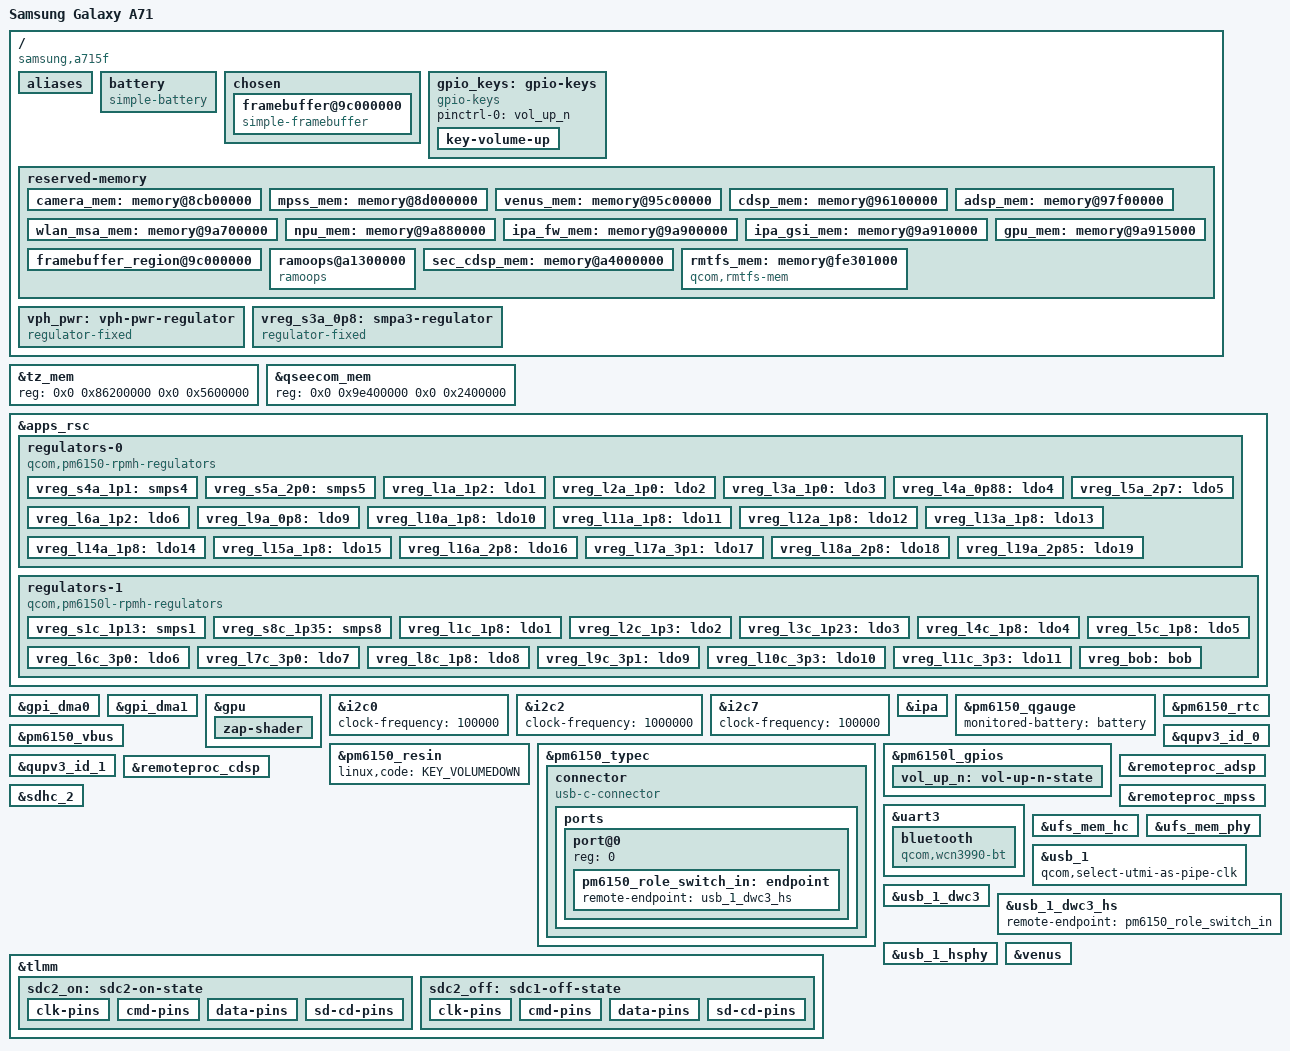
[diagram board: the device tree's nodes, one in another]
// SPDX-License-Identifier: BSD-3-Clause
/*
 * Copyright (c) 2023, Danila Tikhonov <danila@jiaxyga.com>
 * Copyright (c) 2025, Waldemar Tomme <waldetomme@gmail.com>
 */

/dts-v1/;

#include <dt-bindings/arm/qcom,ids.h>
#include <dt-bindings/firmware/qcom,scm.h>
#include <dt-bindings/gpio/gpio.h>
#include <dt-bindings/leds/common.h>
#include <dt-bindings/pinctrl/qcom,pmic-gpio.h>
#include <dt-bindings/regulator/qcom,rpmh-regulator.h>
#include <dt-bindings/usb/pd.h>

#include "sm7150.dtsi"
#include "pm6150.dtsi"
#include "pm6150l.dtsi"

/delete-node/ &camera_mem;
/delete-node/ &mpss_mem;
/delete-node/ &venus_mem;
/delete-node/ &cdsp_mem;
/delete-node/ &adsp_mem;
/delete-node/ &wlan_msa_mem;
/delete-node/ &npu_mem;
/delete-node/ &ipa_fw_mem;
/delete-node/ &ipa_gsi_mem;
/delete-node/ &gpu_mem;
/delete-node/ &sec_cdsp_mem;

/* Increase the size */
&tz_mem {
	reg = <0x0 0x86200000 0x0 0x5600000>;
};

&qseecom_mem {
	reg = <0x0 0x9e400000 0x0 0x2400000>;
};

/ {
	model = "Samsung Galaxy A71";
	compatible = "samsung,a715f", "qcom,sm7150";
	chassis-type = "handset";

	aliases {
		bluetooth0 = &bluetooth;
		hsuart0 = &uart3;
		wifi0 = &wifi;
	};

	battery: battery {
		compatible = "simple-battery";

		voltage-min-design-microvolt = <3400000>;
		voltage-max-design-microvolt = <4400000>;
		charge-full-design-microamp-hours = <4500000>;
	};

	chosen {
		#address-cells = <2>;
		#size-cells = <2>;
		ranges;
		framebuffer@9c000000 {
			compatible = "simple-framebuffer";
			reg = <0x0 0x9c000000 0x0 (1080 * 2400 * 4)>;
			width = <1080>;
			height = <2400>;
			stride = <(1080 * 4)>;
			format = "a8r8g8b8";
			clocks = <&gcc GCC_DISP_HF_AXI_CLK>;
		};
	};

	gpio_keys: gpio-keys {
		compatible = "gpio-keys";
		pinctrl-names = "default";
		pinctrl-0 = <&vol_up_n>;

		key-volume-up {
			label = "Volume Up";
			linux,code = <KEY_VOLUMEUP>;
			gpios = <&pm6150l_gpios 2 GPIO_ACTIVE_LOW>;
			debounce-interval = <15>;
		};
	};

	reserved-memory {
		camera_mem: memory@8cb00000 {
			reg = <0x0 0x8cb00000 0x0 0x500000>;
			no-map;
		};

		mpss_mem: memory@8d000000 {
			reg = <0x0 0x8d000000 0x0 0x8c00000>;
			no-map;
		};

		venus_mem: memory@95c00000 {
			reg = <0x0 0x95c00000 0x0 0x500000>;
			no-map;
		};

		cdsp_mem: memory@96100000 {
			reg = <0x0 0x96100000 0x0 0x1e00000>;
			no-map;
		};

		adsp_mem: memory@97f00000 {
			reg = <0x0 0x97f00000 0x0 0x2800000>;
			no-map;
		};

		wlan_msa_mem: memory@9a700000 {
			reg = <0x0 0x9a700000 0x0 0x180000>;
			no-map;
		};

		npu_mem: memory@9a880000 {
			reg = <0x0 0x9a880000 0x0 0x80000>;
			no-map;
		};

		ipa_fw_mem: memory@9a900000 {
			reg = <0x0 0x9a900000 0x0 0x10000>;
			no-map;
		};

		ipa_gsi_mem: memory@9a910000 {
			reg = <0x0 0x9a910000 0x0 0x5000>;
			no-map;
		};

		gpu_mem: memory@9a915000 {
			reg = <0x0 0x9a915000 0x0 0x2000>;
			no-map;
		};

		framebuffer_region@9c000000 {
			reg = <0x0 0x9c000000 0x0 (1080 * 2400 * 4)>;
			no-map;
		};

		ramoops@a1300000 {
			compatible = "ramoops";
			reg = <0x0 0xa1300000 0x0 0x100000>;

			record-size = <0x40000>;
			pmsg-size = <0x40000>;
			console-size = <0x40000>;
		};

		sec_cdsp_mem: memory@a4000000 {
			reg = <0x0 0xa4000000 0x0 0xc00000>;
			no-map;
		};

		rmtfs_mem: memory@fe301000 {
			compatible = "qcom,rmtfs-mem";
			reg = <0 0xfe301000 0 0x200000>;
			no-map;

			qcom,client-id = <1>;
			qcom,vmid = <15>;
		};
	};

	vph_pwr: vph-pwr-regulator {
		compatible = "regulator-fixed";
		regulator-name = "vph_pwr";
		regulator-min-microvolt = <3700000>;
		regulator-max-microvolt = <3700000>;
	};

	// S3A is really mx.lvl but it's there for supply map completeness sake.
	vreg_s3a_0p8: smpa3-regulator {
		compatible = "regulator-fixed";
		regulator-name = "vreg_s3a_0p8";

		regulator-min-microvolt = <800000>;
		regulator-max-microvolt = <800000>;
		regulator-always-on;
		vin-supply = <&vph_pwr>;
	};
};

&apps_rsc {
	regulators-0 {
		compatible = "qcom,pm6150-rpmh-regulators";
		qcom,pmic-id = "a";

		vdd-s1-supply = <&vph_pwr>;
		vdd-s2-supply = <&vph_pwr>;
		vdd-s3-supply = <&vph_pwr>;
		vdd-s4-supply = <&vph_pwr>;
		vdd-s5-supply = <&vph_pwr>;

		vdd-l1-supply = <&vreg_s8c_1p35>;
		vdd-l2-l3-supply = <&vreg_s4a_1p1>;
		vdd-l4-l7-l8-supply = <&vreg_s4a_1p1>;
		vdd-l5-l16-l17-l18-l19-supply = <&vreg_bob>;
		vdd-l6-supply = <&vreg_s8c_1p35>;
		vdd-l9-supply = <&vreg_s3a_0p8>;
		vdd-l10-l14-l15-supply = <&vreg_s5a_2p0>;
		vdd-l11-l12-l13-supply = <&vreg_s5a_2p0>;

		vreg_s4a_1p1: smps4 {
			regulator-name = "vreg_s4a_1p1";
			regulator-min-microvolt = <824000>;
			regulator-max-microvolt = <1120000>;
		};

		vreg_s5a_2p0: smps5 {
			regulator-name = "vreg_s5a_2p0";
			regulator-min-microvolt = <1744000>;
			regulator-max-microvolt = <2040000>;
		};

		vreg_l1a_1p2: ldo1 {
			regulator-name = "vreg_l1a_1p2";
			regulator-min-microvolt = <1096000>;
			regulator-max-microvolt = <1304000>;
			regulator-initial-mode = <RPMH_REGULATOR_MODE_HPM>;
			regulator-allow-set-load;
			regulator-allowed-modes = <RPMH_REGULATOR_MODE_LPM
						   RPMH_REGULATOR_MODE_HPM>;
		};

		vreg_l2a_1p0: ldo2 {
			regulator-name = "vreg_l2a_1p0";
			regulator-min-microvolt = <944000>;
			regulator-max-microvolt = <1056000>;
			regulator-initial-mode = <RPMH_REGULATOR_MODE_HPM>;
			regulator-allow-set-load;
			regulator-allowed-modes = <RPMH_REGULATOR_MODE_LPM
						   RPMH_REGULATOR_MODE_HPM>;
		};

		vreg_l3a_1p0: ldo3 {
			regulator-name = "vreg_l3a_1p0";
			regulator-min-microvolt = <968000>;
			regulator-max-microvolt = <1064000>;
			regulator-initial-mode = <RPMH_REGULATOR_MODE_HPM>;
			regulator-allow-set-load;
			regulator-allowed-modes = <RPMH_REGULATOR_MODE_LPM
						   RPMH_REGULATOR_MODE_HPM>;
		};

		vreg_l4a_0p88: ldo4 {
			regulator-name = "vreg_l4a_0p88";
			regulator-min-microvolt = <824000>;
			regulator-max-microvolt = <920000>;
			regulator-initial-mode = <RPMH_REGULATOR_MODE_HPM>;
			regulator-allow-set-load;
			regulator-allowed-modes = <RPMH_REGULATOR_MODE_LPM
						   RPMH_REGULATOR_MODE_HPM>;
		};

		vreg_l5a_2p7: ldo5 {
			regulator-name = "vreg_l5a_2p7";
			regulator-min-microvolt = <2600000>;
			regulator-max-microvolt = <2800000>;
			regulator-initial-mode = <RPMH_REGULATOR_MODE_HPM>;
			regulator-allow-set-load;
			regulator-allowed-modes = <RPMH_REGULATOR_MODE_LPM
						   RPMH_REGULATOR_MODE_HPM>;
		};

		vreg_l6a_1p2: ldo6 {
			regulator-name = "vreg_l6a_1p2";
			regulator-min-microvolt = <1096000>;
			regulator-max-microvolt = <1304000>;
			regulator-initial-mode = <RPMH_REGULATOR_MODE_HPM>;
			regulator-allow-set-load;
			regulator-allowed-modes = <RPMH_REGULATOR_MODE_LPM
						   RPMH_REGULATOR_MODE_HPM>;
		};

		vreg_l9a_0p8: ldo9 {
			regulator-name = "vreg_l9a_0p8";
			regulator-min-microvolt = <624000>;
			regulator-max-microvolt = <760000>;
			regulator-initial-mode = <RPMH_REGULATOR_MODE_HPM>;
			regulator-allow-set-load;
			regulator-allowed-modes = <RPMH_REGULATOR_MODE_LPM
						   RPMH_REGULATOR_MODE_HPM>;
		};

		vreg_l10a_1p8: ldo10 {
			regulator-name = "vreg_l10a_1p8";
			regulator-min-microvolt = <1720000>;
			regulator-max-microvolt = <1832000>;
			regulator-initial-mode = <RPMH_REGULATOR_MODE_HPM>;
			regulator-allow-set-load;
			regulator-allowed-modes = <RPMH_REGULATOR_MODE_LPM
						   RPMH_REGULATOR_MODE_HPM>;
		};

		vreg_l11a_1p8: ldo11 {
			regulator-name = "vreg_l11a_1p8";
			regulator-min-microvolt = <1696000>;
			regulator-max-microvolt = <1984000>;
			regulator-initial-mode = <RPMH_REGULATOR_MODE_HPM>;
			regulator-allow-set-load;
			regulator-allowed-modes = <RPMH_REGULATOR_MODE_LPM
						   RPMH_REGULATOR_MODE_HPM>;
		};

		vreg_l12a_1p8: ldo12 {
			regulator-name = "vreg_l12a_1p8";
			regulator-min-microvolt = <1696000>;
			regulator-max-microvolt = <1952000>;
			regulator-initial-mode = <RPMH_REGULATOR_MODE_HPM>;
			regulator-allow-set-load;
			regulator-allowed-modes = <RPMH_REGULATOR_MODE_LPM
						   RPMH_REGULATOR_MODE_HPM>;
		};

		vreg_l13a_1p8: ldo13 {
			regulator-name = "vreg_l13a_1p8";
			regulator-min-microvolt = <1696000>;
			regulator-max-microvolt = <1904000>;
			regulator-initial-mode = <RPMH_REGULATOR_MODE_HPM>;
			regulator-allow-set-load;
			regulator-allowed-modes = <RPMH_REGULATOR_MODE_LPM
						   RPMH_REGULATOR_MODE_HPM>;
		};

		vreg_l14a_1p8: ldo14 {
			regulator-name = "vreg_l14a_1p8";
			regulator-min-microvolt = <1720000>;
			regulator-max-microvolt = <1856000>;
			regulator-initial-mode = <RPMH_REGULATOR_MODE_HPM>;
			regulator-allow-set-load;
			regulator-allowed-modes = <RPMH_REGULATOR_MODE_LPM
						   RPMH_REGULATOR_MODE_HPM>;
		};

		vreg_l15a_1p8: ldo15 {
			regulator-name = "vreg_l15a_1p8";
			regulator-min-microvolt = <1696000>;
			regulator-max-microvolt = <1904000>;
			regulator-initial-mode = <RPMH_REGULATOR_MODE_HPM>;
			regulator-allow-set-load;
			regulator-allowed-modes = <RPMH_REGULATOR_MODE_LPM
						   RPMH_REGULATOR_MODE_HPM>;
		};

		vreg_l16a_2p8: ldo16 {
			regulator-name = "vreg_l16a_2p8";
			regulator-min-microvolt = <2424000>;
			regulator-max-microvolt = <2976000>;
			regulator-initial-mode = <RPMH_REGULATOR_MODE_HPM>;
			regulator-allow-set-load;
			regulator-allowed-modes = <RPMH_REGULATOR_MODE_LPM
						   RPMH_REGULATOR_MODE_HPM>;
		};

		vreg_l17a_3p1: ldo17 {
			regulator-name = "vreg_l17a_3p1";
			regulator-min-microvolt = <3000000>;
			regulator-max-microvolt = <3232000>;
			regulator-initial-mode = <RPMH_REGULATOR_MODE_HPM>;
			regulator-allow-set-load;
			regulator-allowed-modes = <RPMH_REGULATOR_MODE_LPM
						   RPMH_REGULATOR_MODE_HPM>;
		};

		vreg_l18a_2p8: ldo18 {
			regulator-name = "vreg_l18a_2p8";
			regulator-min-microvolt = <2800000>;
			regulator-max-microvolt = <3000000>;
			regulator-initial-mode = <RPMH_REGULATOR_MODE_HPM>;
			regulator-allow-set-load;
			regulator-allowed-modes = <RPMH_REGULATOR_MODE_LPM
						   RPMH_REGULATOR_MODE_HPM>;
		};

		vreg_l19a_2p85: ldo19 {
			regulator-name = "vreg_l19a_2p85";
			regulator-min-microvolt = <2944000>;
			regulator-max-microvolt = <3304000>;
			regulator-initial-mode = <RPMH_REGULATOR_MODE_HPM>;
			regulator-allow-set-load;
			regulator-allowed-modes = <RPMH_REGULATOR_MODE_LPM
						   RPMH_REGULATOR_MODE_HPM>;
		};
	};

	regulators-1 {
		compatible = "qcom,pm6150l-rpmh-regulators";
		qcom,pmic-id = "c";

		vdd-s1-supply = <&vph_pwr>;
		vdd-s2-supply = <&vph_pwr>;
		vdd-s3-supply = <&vph_pwr>;
		vdd-s4-supply = <&vph_pwr>;
		vdd-s5-supply = <&vph_pwr>;
		vdd-s6-supply = <&vph_pwr>;
		vdd-s7-supply = <&vph_pwr>;
		vdd-s8-supply = <&vph_pwr>;

		vdd-l2-l3-supply = <&vreg_s8c_1p35>;
		vdd-l4-l5-l6-supply = <&vreg_bob>;
		vdd-l7-l11-supply = <&vreg_bob>;
		vdd-l9-l10-supply = <&vreg_bob>;

		vdd-bob-supply = <&vph_pwr>;
		vdd-flash-supply = <&vreg_bob>;
		vdd-rgb-supply = <&vreg_bob>;

		vreg_s1c_1p13: smps1 {
			regulator-name = "vreg_s1c_1p13";
			regulator-min-microvolt = <1000000>;
			regulator-max-microvolt = <1200000>;
		};

		vreg_s8c_1p35: smps8 {
			regulator-name = "vreg_s8c_1p35";
			regulator-min-microvolt = <1120000>;
			regulator-max-microvolt = <1408000>;
		};

		vreg_l1c_1p8: ldo1 {
			regulator-name = "vreg_l1c_1p8";
			regulator-min-microvolt = <1616000>;
			regulator-max-microvolt = <1984000>;
			regulator-initial-mode = <RPMH_REGULATOR_MODE_HPM>;
			regulator-allow-set-load;
			regulator-allowed-modes = <RPMH_REGULATOR_MODE_LPM
						   RPMH_REGULATOR_MODE_HPM>;
		};

		vreg_l2c_1p3: ldo2 {
			regulator-name = "vreg_l2c_1p3";
			regulator-min-microvolt = <1200000>;
			regulator-max-microvolt = <1352000>;
			regulator-initial-mode = <RPMH_REGULATOR_MODE_HPM>;
			regulator-allow-set-load;
			regulator-allowed-modes = <RPMH_REGULATOR_MODE_LPM
						   RPMH_REGULATOR_MODE_HPM>;
		};

		vreg_l3c_1p23: ldo3 {
			regulator-name = "vreg_l3c_1p23";
			regulator-min-microvolt = <1144000>;
			regulator-max-microvolt = <1256000>;
			regulator-initial-mode = <RPMH_REGULATOR_MODE_HPM>;
			regulator-allow-set-load;
			regulator-allowed-modes = <RPMH_REGULATOR_MODE_LPM
						   RPMH_REGULATOR_MODE_HPM>;
		};

		vreg_l4c_1p8: ldo4 {
			regulator-name = "vreg_l4c_1p8";
			regulator-min-microvolt = <1648000>;
			regulator-max-microvolt = <2950000>;
			regulator-initial-mode = <RPMH_REGULATOR_MODE_HPM>;
			regulator-allow-set-load;
			regulator-allowed-modes = <RPMH_REGULATOR_MODE_LPM
						   RPMH_REGULATOR_MODE_HPM>;
		};

		vreg_l5c_1p8: ldo5 {
			regulator-name = "vreg_l5c_1p8";
			regulator-min-microvolt = <1648000>;
			regulator-max-microvolt = <2950000>;
			regulator-initial-mode = <RPMH_REGULATOR_MODE_HPM>;
			regulator-allow-set-load;
			regulator-allowed-modes = <RPMH_REGULATOR_MODE_LPM
						   RPMH_REGULATOR_MODE_HPM>;
		};

		vreg_l6c_3p0: ldo6 {
			regulator-name = "vreg_l6c_3p0";
			regulator-min-microvolt = <1648000>;
			regulator-max-microvolt = <3100000>;
			regulator-initial-mode = <RPMH_REGULATOR_MODE_HPM>;
			regulator-allow-set-load;
			regulator-allowed-modes = <RPMH_REGULATOR_MODE_LPM
						   RPMH_REGULATOR_MODE_HPM>;
		};

		vreg_l7c_3p0: ldo7 {
			regulator-name = "vreg_l7c_3p0";
			regulator-min-microvolt = <3000000>;
			regulator-max-microvolt = <3312000>;
			regulator-initial-mode = <RPMH_REGULATOR_MODE_HPM>;
			regulator-allow-set-load;
			regulator-allowed-modes = <RPMH_REGULATOR_MODE_LPM
						   RPMH_REGULATOR_MODE_HPM>;
		};

		vreg_l8c_1p8: ldo8 {
			regulator-name = "vreg_l8c_1p8";
			regulator-min-microvolt = <1800000>;
			regulator-max-microvolt = <1900000>;
			regulator-initial-mode = <RPMH_REGULATOR_MODE_HPM>;
			regulator-allow-set-load;
			regulator-allowed-modes = <RPMH_REGULATOR_MODE_LPM
						   RPMH_REGULATOR_MODE_HPM>;
		};

		/*
		 * Downstream specifies a range of 2950-3312mV.
		 * Tighten the range to 2950-3100mV.
		 */
		vreg_l9c_3p1: ldo9 {
			regulator-name = "vreg_l9c_3p1";
			regulator-min-microvolt = <2950000>;
			regulator-max-microvolt = <3100000>;
			regulator-initial-mode = <RPMH_REGULATOR_MODE_HPM>;
			regulator-allow-set-load;
			regulator-allowed-modes = <RPMH_REGULATOR_MODE_LPM
						   RPMH_REGULATOR_MODE_HPM>;
		};

		vreg_l10c_3p3: ldo10 {
			regulator-name = "vreg_l10c_3p3";
			regulator-min-microvolt = <3200000>;
			regulator-max-microvolt = <3312000>;
			regulator-initial-mode = <RPMH_REGULATOR_MODE_HPM>;
			regulator-allow-set-load;
			regulator-allowed-modes = <RPMH_REGULATOR_MODE_LPM
						   RPMH_REGULATOR_MODE_HPM>;
		};

		vreg_l11c_3p3: ldo11 {
			regulator-name = "vreg_l11c_3p3";
			regulator-min-microvolt = <2950000>;
			regulator-max-microvolt = <3400000>;
			regulator-initial-mode = <RPMH_REGULATOR_MODE_HPM>;
			regulator-allow-set-load;
			regulator-allowed-modes = <RPMH_REGULATOR_MODE_LPM
						   RPMH_REGULATOR_MODE_HPM>;
		};

		vreg_bob: bob {
			regulator-name = "vreg_bob";
			regulator-min-microvolt = <3296000>;
			regulator-max-microvolt = <3960000>;
			regulator-initial-mode = <RPMH_REGULATOR_MODE_AUTO>;
			regulator-allow-bypass;
		};
	};
};

&gpi_dma0 {
	status = "okay";
};

&gpi_dma1 {
	status = "okay";
};

&gpu {
	zap-shader {
		firmware-name = "qcom/sm7150/samsung/a715f/a615_zap.mbn";
	};
};

&i2c0 {
	clock-frequency = <100000>;
	status = "okay";

	// tas2562@4c
};

&i2c2 {
	clock-frequency = <1000000>;
	status = "okay";

	// nq@28
	// pn547@2B
};

&i2c7 {
	clock-frequency = <100000>;
	status = "okay";

	// st_fts@49
	// synaptics_dsx@20
	// touchscreen@48
};

// NOTE: i2c9 is enabled downstream but no device is connected

&ipa {
	memory-region = <&ipa_fw_mem>;
	firmware-name = "qcom/sm7150/samsung/a715f/ipa_fws.mbn";
	status = "okay";
};

&pm6150_qgauge {
	monitored-battery = <&battery>;
	status = "okay";
};

&pm6150_resin {
	linux,code = <KEY_VOLUMEDOWN>;
	status = "okay";
};

&pm6150_rtc {
	status = "okay";
};

&pm6150_typec {
	vdd-vbus-supply = <&pm6150_vbus>;
	vdd-pdphy-supply = <&vreg_l17a_3p1>;
	status = "okay";

	connector {
		compatible = "usb-c-connector";

		power-role = "source";
		data-role = "dual";
		self-powered;

		source-pdos = <PDO_FIXED(5000, 3000, PDO_FIXED_DUAL_ROLE |
			       PDO_FIXED_USB_COMM | PDO_FIXED_DATA_SWAP)>;

		ports {
			#address-cells = <1>;
			#size-cells = <0>;

			port@0 {
				reg = <0>;
				pm6150_role_switch_in: endpoint {
					remote-endpoint = <&usb_1_dwc3_hs>;
				};
			};
		};
	};
};

&pm6150_vbus {
	regulator-min-microamp = <500000>;
	regulator-max-microamp = <3000000>;
	status = "okay";
};

&pm6150l_gpios {
	vol_up_n: vol-up-n-state {
		pins = "gpio2";
		function = PMIC_GPIO_FUNC_NORMAL;
		input-enable;
		bias-pull-up;
		power-source = <0>;
	};
};

&qupv3_id_0 {
	status = "okay";
};

&qupv3_id_1 {
	status = "okay";
};

&remoteproc_adsp {
	firmware-name = "qcom/sm7150/samsung/a715f/adsp.mbn";
	status = "okay";
};

&remoteproc_cdsp {
	firmware-name = "qcom/sm7150/samsung/a715f/cdsp.mbn";
	status = "okay";
};

&remoteproc_mpss {
	firmware-name = "qcom/sm7150/samsung/a715f/modem.mbn";
	status = "okay";
};

&sdhc_2 {
	cd-gpios = <&tlmm 69 GPIO_ACTIVE_HIGH>;

	vmmc-supply = <&vreg_l9c_3p1>;
	vqmmc-supply = <&vreg_l6c_3p0>;

	pinctrl-names = "default", "sleep";
	pinctrl-0 = <&sdc2_on>;
	pinctrl-1 = <&sdc2_off>;

	status = "okay";
};

&tlmm {
	/*
	 * gpio0, gpio1, gpio2, gpio3 -> spi1 -> NFC
	 * gpio59, gpio60, gpio61, gpio62 -> spi6 -> fingerprint sensor
	 * gpio83, gpio84 -> ???
	*/
	gpio-reserved-ranges = <0 4>, <59 4>, <83 2>;

	gpio-line-names =
		"", /* GPIO_0 */
		"",
		"",
		"",
		"",
		"",
		"",
		"",
		"",
		"",
		"", /* GPIO_10 */
		"reset_gpio",
		"",
		"",
		"",
		"",
		"",
		"",
		"",
		"",
		"", /* GPIO_20 */
		"",
		"",
		"",
		"",
		"",
		"",
		"",
		"",
		"",
		"", /* GPIO_30 */
		"",
		"",
		"",
		"",
		"",
		"",
		"",
		"",
		"",
		"", /* GPIO_40 */
		"",
		"",
		"",
		"",
		"",
		"",
		"",
		"",
		"",
		"", /* GPIO_50 */
		"",
		"",
		"",
		"",
		"",
		"",
		"",
		"",
		"",
		"", /* GPIO_60 */
		"",
		"",
		"",
		"",
		"",
		"",
		"",
		"",
		"",
		"", /* GPIO_70 */
		"",
		"",
		"",
		"",
		"",
		"",
		"",
		"",
		"",
		"", /* GPIO_80 */
		"",
		"",
		"",
		"",
		"",
		"",
		"",
		"",
		"",
		"", /* GPIO_90 */
		"",
		"",
		"",
		"",
		"",
		"",
		"",
		"",
		"",
		"", /* GPIO_100 */
		"",
		"",
		"",
		"",
		"",
		"",
		"",
		"",
		"",
		"", /* GPIO_110 */
		"",
		"",
		"",
		"",
		"",
		"",
		"",
		"";

	sdc2_on: sdc2-on-state {
		clk-pins {
			pins = "sdc2_clk";
			bias-disable;
			drive-strength = <16>;
		};

		cmd-pins {
			pins = "sdc2_cmd";
			bias-pull-up;
			drive-strength = <10>;
		};

		data-pins {
			pins = "sdc2_data";
			bias-pull-up;
			drive-strength = <10>;
		};

		sd-cd-pins {
			pins = "gpio69";
			function = "gpio";
			bias-pull-up;
			drive-strength = <2>;
		};
	};

	sdc2_off: sdc1-off-state {
		clk-pins {
			pins = "sdc2_clk";
			bias-disable;
			drive-strength = <2>;
		};

		cmd-pins {
			pins = "sdc2_cmd";
			bias-pull-up;
			drive-strength = <2>;
		};

		data-pins {
			pins = "sdc2_data";
			bias-pull-up;
			drive-strength = <2>;
		};

		sd-cd-pins {
			pins = "gpio69";
			function = "gpio";
			bias-pull-up;
			drive-strength = <2>;
		};
	};
};

&uart3 {
	/delete-property/interrupts;
	interrupts-extended = <&intc GIC_SPI 604 IRQ_TYPE_LEVEL_HIGH>,
			      <&tlmm 41 IRQ_TYPE_EDGE_FALLING>;
	pinctrl-names = "default", "sleep";
	pinctrl-1 = <&qup_uart3_default>;
	status = "okay";

	bluetooth: bluetooth {
		compatible = "qcom,wcn3990-bt";

		vddio-supply = <&vreg_l10a_1p8>;
		vddxo-supply = <&vreg_l1c_1p8>;
		vddrf-supply = <&vreg_l2c_1p3>;
		vddch0-supply = <&vreg_l10c_3p3>;
		max-speed = <3200000>;
	};
};

&ufs_mem_hc {
	vcc-supply = <&vreg_l19a_2p85>;
	vcc-max-microamp = <600000>;
	vccq2-supply = <&vreg_l12a_1p8>;
	vccq2-max-microamp = <600000>;
	status = "okay";
};

&ufs_mem_phy {
	vdda-phy-supply = <&vreg_l4a_0p88>;
	vdda-pll-supply = <&vreg_l3c_1p23>;
	status = "okay";
};

&usb_1 {
	qcom,select-utmi-as-pipe-clk;
	status = "okay";
};

&usb_1_dwc3 {
	dr_mode = "otg";
	usb-role-switch;
	maximum-speed = "high-speed";
};

&usb_1_dwc3_hs {
	remote-endpoint = <&pm6150_role_switch_in>;
};

&usb_1_hsphy {
	vdd-supply = <&vreg_l4a_0p88>;
	vdda-pll-supply = <&vreg_l11a_1p8>;
	vdda-phy-dpdm-supply = <&vreg_l17a_3p1>;
	status = "okay";
};

&venus {
	firmware-name = "qcom/sm7150/samsung/a715f/venus.mbn";
};
